# Secure_IoT register map
Vendor: Mindgrove Technologies Private Limited; Series: Mindgrove Silicon; File version: 1.0.0
CPU: VAJRA r1p9, little endian, MPU, FPU, double-precision FPU, I-cache, D-cache, 7 interrupt priority bits
Registers are 32-bit, read-write, reset 0x0 unless marked. A register's access mark holds for its fields unless they carry their own. Offsets are from the block's base; [hi:lo] are bit positions.

## GPTIMER0 — General purpose timer
Base 0x00044200
Same registers: GPTIMER1 0x00044220, GPTIMER2 0x00044240, GPTIMER3 0x00044260
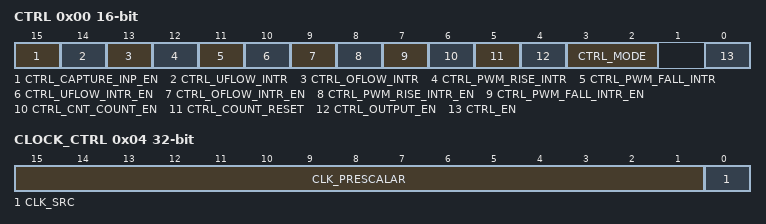
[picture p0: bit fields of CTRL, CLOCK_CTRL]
0x00 CTRL 16-bit — Control register
  [15] CTRL_CAPTURE_INP_EN — Counter capture input enable
  [14] CTRL_UFLOW_INTR ro — Counter underflow interrupt bit
  [13] CTRL_OFLOW_INTR ro — Counter overflow interrupt bit
  [12] CTRL_PWM_RISE_INTR ro — PWM rise interupt bit
  [11] CTRL_PWM_FALL_INTR ro — PWM fall interupt bit
  [10] CTRL_UFLOW_INTR_EN — Counter underflow interrupt enable
  [9] CTRL_OFLOW_INTR_EN — Counter overflow interrupt enable
  [8] CTRL_PWM_RISE_INTR_EN — PWM rise interupt enable
  [7] CTRL_PWM_FALL_INTR_EN — PWM fall interupt enable
  [6] CTRL_CNT_COUNT_EN — Timer continuous count enable
  [5] CTRL_COUNT_RESET — Timer counter reset bit
  [4] CTRL_OUTPUT_EN — Timer output enable bit
  [3:2] CTRL_MODE — Timer mode select: 0=PWM, 1=Down, 2=Up, 3=UpDown
  [0] CTRL_EN — Timer enable flag
0x04 CLOCK_CTRL — Clock control register
  [15:1] CLK_PRESCALAR — GPTIMER prescalar value
  [0] CLK_SRC — GPTIMER clock select bit
0x08 COUNT ro — Counter register
0x0C RPTD_COUNT ro — Repeated count register
0x10 DUTY_CYCLE — PWM duty cycle register
0x14 PERIOD — PWM period register
0x18 CAPTURE_INP — Timer capture input register

## CLINT0 — Core Local Interrupt Controller
Base 0x02000000
0x00 MSIP — Machine Software interrupt pending register
0x4000 TIMECMP 64-bit (reset mask 0xFFFFFFFF) — Time compare register
0xBFF8 TIME 64-bit (reset mask 0xFFFFFFFF) — System Time register - low

## UART0 — Universal asynchronous receiver and transmitter
Base 0x00011300
Same registers: UART1 0x00011400, UART2 0x00011500
0x00 BAUD_REG 16-bit — Baud register
0x04 TX_REG — TX data register
0x08 RX_REG — RX data register
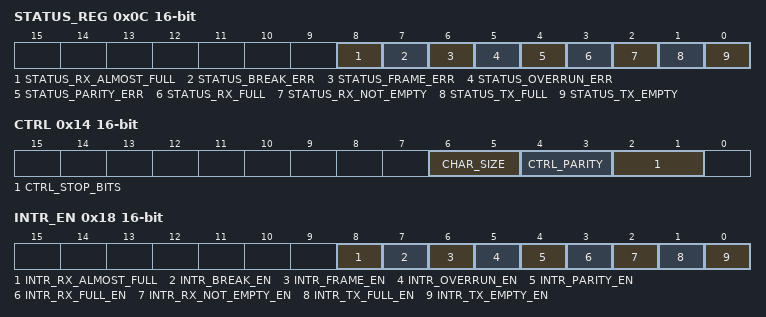
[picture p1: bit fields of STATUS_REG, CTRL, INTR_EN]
0x0C STATUS_REG 16-bit — UART Status register
  [8] STATUS_RX_ALMOST_FULL — Indicates that the RXFIFO is almost full depending on RX_threshold register
  [7] STATUS_BREAK_ERR — Break error flag
  [6] STATUS_FRAME_ERR — Frame error flag
  [5] STATUS_OVERRUN_ERR — Overrun error flag
  [4] STATUS_PARITY_ERR — Parity error in received data flag
  [3] STATUS_RX_FULL — Receiver register full flag
  [2] STATUS_RX_NOT_EMPTY — Receiver register not empty flag
  [1] STATUS_TX_FULL — Transmittor register full flag
  [0] STATUS_TX_EMPTY — Transmittor register empty flag
0x10 DELAY_REG 16-bit — Stores the delay to have before Tranmission
0x14 CTRL 16-bit — Control register
  [6:5] CHAR_SIZE — Selects the transmission data size 00 - 8 bits, 01 - 7 bits, 10 - 6 bits, 11 - 5 bits
  [4:3] CTRL_PARITY — To select the type of parity. 00 - None, 01 - Odd, 10 - Even
  [2:1] CTRL_STOP_BITS — To select the number of stop bits. 00 - 1 Stop bits, 01 - 1.5 Stop bits, 10 - 2 Stop bits
0x18 INTR_EN 16-bit — Interrupts enable register
  [8] INTR_RX_ALMOST_FULL — Enable for interrupt RX fifo almost full depending on the RX_threshold register
  [7] INTR_BREAK_EN — Enable for interrupt of break error
  [6] INTR_FRAME_EN — Enable for interrupt of frame error
  [5] INTR_OVERRUN_EN — Enable for interrupt of overrun error
  [4] INTR_PARITY_EN — Enable for interrupt of parity error
  [3] INTR_RX_FULL_EN — Enable for interrupt of receiver fifo full
  [2] INTR_RX_NOT_EMPTY_EN — Enable for interrupt of receiver fifo not empty
  [1] INTR_TX_FULL_EN — Enable for interrupt of transmission fifo full
  [0] INTR_TX_EMPTY_EN — Enable for interrupt of transmission fifo empty
0x1C RX_THRESHOLD 8-bit — The threshold value to indicate the RX FIFO almost full interrupt
